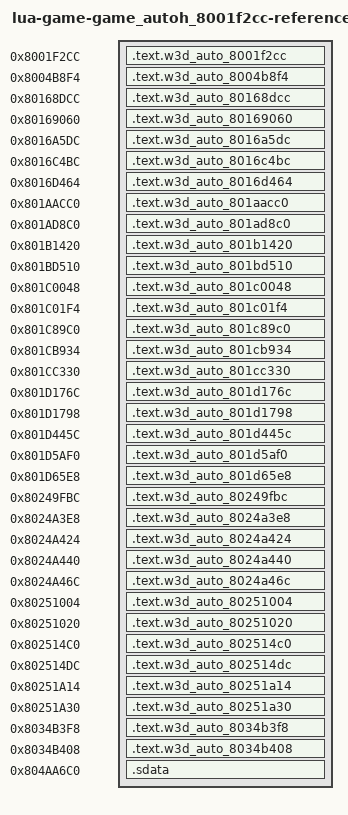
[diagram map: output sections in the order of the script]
/* Generated reference-only placements. All bodies are source-built. */
OUTPUT_FORMAT("elf32-powerpc")
OUTPUT_ARCH(powerpc)
ENTRY(w3d_auto_8001f2cc)
_SDA_BASE_ = 0x804b2540;
_SDA2_BASE_ = 0x804c2540;
fn_8001F25C = 0x8001f25c;
fn_8016803C = 0x8016803c;
fn_8016804C = 0x8016804c;
fn_80168744 = 0x80168744;
fn_8016CD38 = 0x8016cd38;
fn_801AD168 = 0x801ad168;
fn_801B529C = 0x801b529c;
fn_801BFE64 = 0x801bfe64;
fn_801CB41C = 0x801cb41c;
fn_801D4544 = 0x801d4544;
fn_801D60CC = 0x801d60cc;
fn_801D6220 = 0x801d6220;
lbl_803ABB34 = 0x803abb34;
lbl_803AC284 = 0x803ac284;
lbl_803AC288 = 0x803ac288;
lbl_803AC300 = 0x803ac300;
lbl_803AC304 = 0x803ac304;
lbl_803AC308 = 0x803ac308;
lbl_803ADF60 = 0x803adf60;
lbl_803AE240 = 0x803ae240;
lbl_803AE244 = 0x803ae244;
lbl_80414E98 = 0x80414e98;
lbl_80414EC0 = 0x80414ec0;
lbl_804151B8 = 0x804151b8;
lbl_804160F0 = 0x804160f0;
lbl_804161E0 = 0x804161e0;
SECTIONS {
  .text.w3d_auto_8001f2cc 0x8001f2cc : { *(.text.w3d_auto_8001f2cc) }
  .text.w3d_auto_8004b8f4 0x8004b8f4 : { *(.text.w3d_auto_8004b8f4) }
  .text.w3d_auto_80168dcc 0x80168dcc : { *(.text.w3d_auto_80168dcc) }
  .text.w3d_auto_80169060 0x80169060 : { *(.text.w3d_auto_80169060) }
  .text.w3d_auto_8016a5dc 0x8016a5dc : { *(.text.w3d_auto_8016a5dc) }
  .text.w3d_auto_8016c4bc 0x8016c4bc : { *(.text.w3d_auto_8016c4bc) }
  .text.w3d_auto_8016d464 0x8016d464 : { *(.text.w3d_auto_8016d464) }
  .text.w3d_auto_801aacc0 0x801aacc0 : { *(.text.w3d_auto_801aacc0) }
  .text.w3d_auto_801ad8c0 0x801ad8c0 : { *(.text.w3d_auto_801ad8c0) }
  .text.w3d_auto_801b1420 0x801b1420 : { *(.text.w3d_auto_801b1420) }
  .text.w3d_auto_801bd510 0x801bd510 : { *(.text.w3d_auto_801bd510) }
  .text.w3d_auto_801c0048 0x801c0048 : { *(.text.w3d_auto_801c0048) }
  .text.w3d_auto_801c01f4 0x801c01f4 : { *(.text.w3d_auto_801c01f4) }
  .text.w3d_auto_801c89c0 0x801c89c0 : { *(.text.w3d_auto_801c89c0) }
  .text.w3d_auto_801cb934 0x801cb934 : { *(.text.w3d_auto_801cb934) }
  .text.w3d_auto_801cc330 0x801cc330 : { *(.text.w3d_auto_801cc330) }
  .text.w3d_auto_801d176c 0x801d176c : { *(.text.w3d_auto_801d176c) }
  .text.w3d_auto_801d1798 0x801d1798 : { *(.text.w3d_auto_801d1798) }
  .text.w3d_auto_801d445c 0x801d445c : { *(.text.w3d_auto_801d445c) }
  .text.w3d_auto_801d5af0 0x801d5af0 : { *(.text.w3d_auto_801d5af0) }
  .text.w3d_auto_801d65e8 0x801d65e8 : { *(.text.w3d_auto_801d65e8) }
  .text.w3d_auto_80249fbc 0x80249fbc : { *(.text.w3d_auto_80249fbc) }
  .text.w3d_auto_8024a3e8 0x8024a3e8 : { *(.text.w3d_auto_8024a3e8) }
  .text.w3d_auto_8024a424 0x8024a424 : { *(.text.w3d_auto_8024a424) }
  .text.w3d_auto_8024a440 0x8024a440 : { *(.text.w3d_auto_8024a440) }
  .text.w3d_auto_8024a46c 0x8024a46c : { *(.text.w3d_auto_8024a46c) }
  .text.w3d_auto_80251004 0x80251004 : { *(.text.w3d_auto_80251004) }
  .text.w3d_auto_80251020 0x80251020 : { *(.text.w3d_auto_80251020) }
  .text.w3d_auto_802514c0 0x802514c0 : { *(.text.w3d_auto_802514c0) }
  .text.w3d_auto_802514dc 0x802514dc : { *(.text.w3d_auto_802514dc) }
  .text.w3d_auto_80251a14 0x80251a14 : { *(.text.w3d_auto_80251a14) }
  .text.w3d_auto_80251a30 0x80251a30 : { *(.text.w3d_auto_80251a30) }
  .text.w3d_auto_8034b3f8 0x8034b3f8 : { *(.text.w3d_auto_8034b3f8) }
  .text.w3d_auto_8034b408 0x8034b408 : { *(.text.w3d_auto_8034b408) }
  .sdata 0x804aa6c0 (NOLOAD) : {
    . = 0x0; lbl_804AA6C0 = .;
    . = 0x70cc; lbl_804B178C = .;
    . = 0x70e8; lbl_804B17A8 = .;
    . = 0x70ec; lbl_804B17AC = .;
    . = 0x71c4; lbl_804B1884 = .;
    . += 1; }
  /DISCARD/ : { *(.text*) *(.rodata*) *(.data*) *(.bss*) *(.sdata*) *(.sbss*) *(.comment) }
}
